# netx90_app register map
File version: 1.0
CPU: CM4 r0p1, little endian, MPU, FPU, 4 interrupt priority bits, 78 interrupts
Registers are 32-bit, read-write, reset 0x0 unless marked. A register's access mark holds for its fields unless they carry their own. Offsets are from the block's base; [hi:lo] are bit positions; {n}, {i} and the like mark numbered series; 'fields as' and 'values as' point back to an identical list; <NAME> marks a mode.

## mpwm_app
Base 0xFF802400
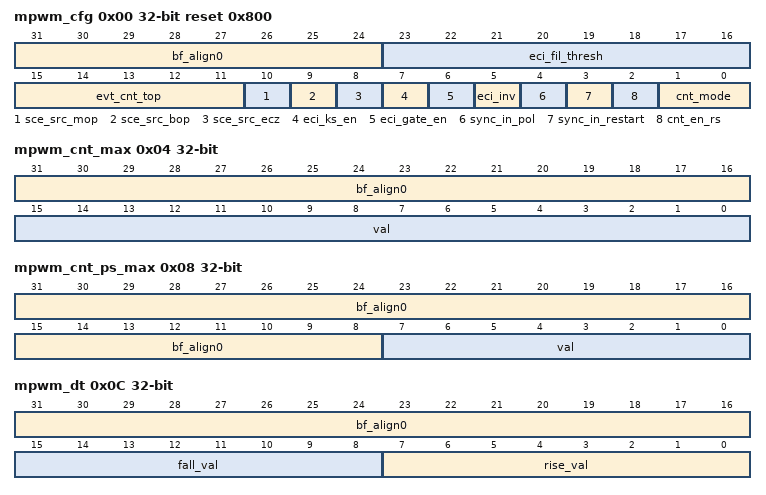
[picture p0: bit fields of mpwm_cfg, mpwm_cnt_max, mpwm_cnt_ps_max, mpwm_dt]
0x00 mpwm_cfg reset 0x800 (reset mask 0xFFFFFF) — Config register: General config bits for the MPWM module.
  [31:24] bf_align0 — bitField alignment value for aeabi compatibility
  [23:16] eci_fil_thresh — ECI filter threshold: Threshold value for the error condition input integral filter.
  [15:11] evt_cnt_top — evt_cnt_top Used to specify the maximum value of EVT_CNT. When EVT_CNT is zero and a begin of period )BOP) event occurs, an event counter zero (ECZ) event is emitted and EVT_CNT is reset to evt_cnt_top. If an begin of period event occurs and EVT_CNT is not zero, EVT_CNT is decremented. This mechanism can be used as an event prescaler to reduce the number of period interrupts from the MPWM module. Examples: If evt_cnt_top is zero, ECZ events and BOP events will coincide. If evt_cnt_top is one, ECZ events will appear every other period (half the frequency of BOP events). If evt_cnt_top is two, ECZ events will appear every third period (one third the frequency of BOP events).
  [10] sce_src_mop — sce_src_mop 1=emit shadow copy event on middle of PWM period bit
  [9] sce_src_bop — sce_src_bop 1=emit shadow copy event on beginning of PWM period
  [8] sce_src_ecz — sce_src_ecz 1=emit shadow copy event when event counter reaches zero
  [7] eci_ks_en — eci_ks_en Set 1 to enable synchronous error condition input (eci) kill switch. The synchronous eci kill switch is a flip flop that is set once eci is active. The eci kill switch can only be reset through MPWM_ECI_CMD. When the eci kill switch is set, all PWM module outputs are disabled.
  [6] eci_gate_en — eci_gate_en Set 1 to gate all pwm outputs with the integral filtered error control input. This means that the outputs will be disabled asynchronously whenever eci is active.
  [5] eci_inv — eci_inv This bit controls the polarity of the error condition input (eci). Set 0 for active high eci, 1 for active low eci.
  [4] sync_in_pol — Polarity of sync signal from trigger_latch unit 0: Sync on rising edge 1: Sync on falling edge
  [3] sync_in_restart — Restart at sync signal from trigger_latch unit 0: Restart counter only by restart command. 1: Restart counter at sync signal or by restart command.
  [2] cnt_en_rs — cnt_en_rs When this bit is one and sync_in is active, save the value of MPWM_CNT to the MPWM_CNT_RS (rs = read sync) register.
  [1:0] cnt_mode — Counter mode: 00: sawtooth 01: triangle 10: inv sawtooth 11: inv triangle
0x04 mpwm_cnt_max (reset mask 0xFFFF) — Counter top register: This is the maximum / top value for the PWM counter. In inverse sawtooth mode, MPWM_CNT will be loaded with MPWM_CNT_MAX after reaching zero or when restarting the counter. In sawtooth mode, MPWM_CNT will be reset to zero after reaching MPWM_CNT_MAX. In inverse sawtooth mode, MPWM_CNT will be set to MPWM_CNT_MAX when restarting the counter, and when it reaches MPWM_CNT_MAX while counting up, it will change to counting down. In inverse sawtooth mode, when MPWM_CNT reaches MPWM_CNT_MAX while counting up, it will change to counting down. In either sawtooth mode, the most significant bit must be zero. This is necessary to ensure a valid MPWM_ECNT. The CNT_MAX register must be at least 1 for correct operation of the counter.
  [31:16] bf_align0 — bitField alignment value for aeabi compatibility
  [15:0] val — Counter top value
0x08 mpwm_cnt_ps_max (reset mask 0xFF) — Counter prescaler max value register: The values of this register determines how often MPWM_CNT and the counters in the dead time generators will be updated. When setting MPWM_CNT_PS_MAX to n, MPWM_CNT will be updated every n + 1 system clock cycles. This register can be used to slow down operation of the counter.
  [31:8] bf_align0 — bitField alignment value for aeabi compatibility
  [7:0] val — Counter prescaler max value
0x0C mpwm_dt (reset mask 0xFFFF) — Dead time register: This is the number of dead (LS and HS off) cycles (prescaled by MPWM_CNT_PS) that the dead time generator inserts when the direct PWM signal changes from zero to one (rise_val) and from one to zero (fall_val). Set to zero for no dead cycles.
  [31:16] bf_align0 — bitField alignment value for aeabi compatibility
  [15:8] fall_val — Dead time cycles at falling edge of PWM signal
  [7:0] rise_val — Dead time cycles at rising edge of PWM signal
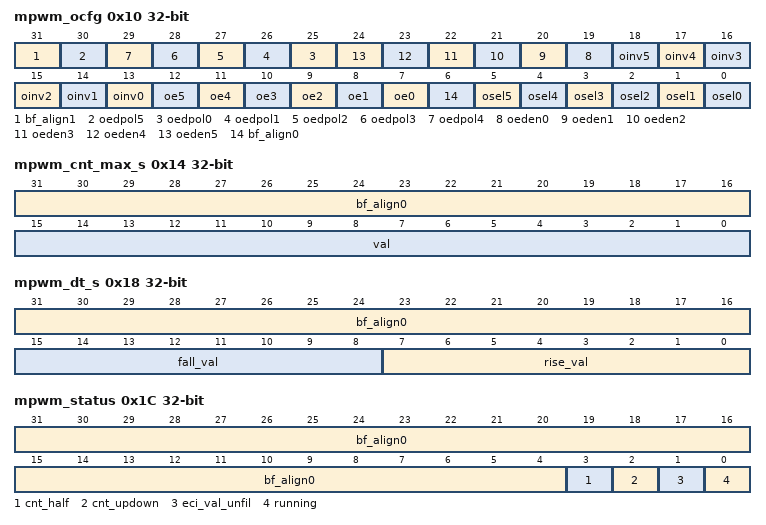
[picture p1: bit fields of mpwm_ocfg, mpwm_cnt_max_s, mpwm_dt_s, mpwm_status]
0x10 mpwm_ocfg (reset mask 0x7FFFFFBF) — Output section config register: Output select, enable, invert and edge detect values.
  [31] bf_align1 — bitField alignment value for aeabi compatibility
  [30] oedpol5 — Channel 5 edge detector polarity (0 = detect positive edge, 1 = detect negative edge)
  [n+25] oedpol{n} (n=0..4) — Channel {n} edge detector polarity
  [n+19] oeden{n} (n=0..5) — Channel {n} edge detector enable
  [n+13] oinv{n} (n=1..5) — Output {n} invert
  [13] oinv0 — Output 0 invert (see output section diagram)
  [n+7] oe{n} (n=1..5) — Output {n} enable
  [7] oe0 — Output 0 enable (see output section diagram)
  [6] bf_align0 — bitField alignment value for aeabi compatibility
  [5] osel5 — Output 5 selector: 0: compare channel 5 direct PWM output 1: dead time generator channel 2 LS
  [4] osel4 — Output 4 selector: 0: compare channel 4 direct PWM output 1: dead time generator channel 2 HS
  [3] osel3 — Output 3 selector: 0: compare channel 3 direct PWM output 1: dead time generator channel 1 LS
  [2] osel2 — Output 2 selector: 0: compare channel 2 direct PWM output 1: dead time generator channel 1 HS
  [1] osel1 — Output 1 selector: 0: compare channel 1 direct PWM output 1: dead time generator channel 0 LS
  [0] osel0 — Output 0 selector: 0: compare channel 0 direct PWM output 1: dead time generator channel 0 HS
0x14 mpwm_cnt_max_s (reset mask 0xFFFF) — Counter top shadow register: Shadow register for MPWM_CNT_TOP. After writing this register, an internal flag is set. If the internal flag is set, at the next occurence of a shadow copy event cnt_top will be overwritten by MPWM_CNT_MAX_S and the internal flag will be reset.
  [31:16] bf_align0 — bitField alignment value for aeabi compatibility
  [15:0] val — Counter top shadow value
0x18 mpwm_dt_s (reset mask 0xFFFF) — Dead time shadow register: Shadow register for MPWM_DT register.
  [31:16] bf_align0 — bitField alignment value for aeabi compatibility
  [15:8] fall_val — Dead time shadow value for falling edge of PWM signal
  [7:0] rise_val — Dead time shadow value for rising edge of PWM signal
0x1C mpwm_status ro (reset mask 0xF) — Status register: This register can be read to obtain information about the current status of the MPWM module.
  [31:4] bf_align0 — bitField alignment value for aeabi compatibility
  [3] cnt_half — count half: 0: counter is in first half period of triangle mode or inverted triangle mode or counter is in sawtooth or inverse sawtooth mode. 1: counter is in second half period of triangle mode or inverted triangle mode
  [2] cnt_updown — count updown 0: counter is counting down 1: counter is counting up
  [1] eci_val_unfil — Error Condition Input unfiltered: Read the current value of the error condition input before the digital integral filter. This bit is corrected for polarity, which means it reads zero for inactive, one for active.
  [0] running — MPWM is running
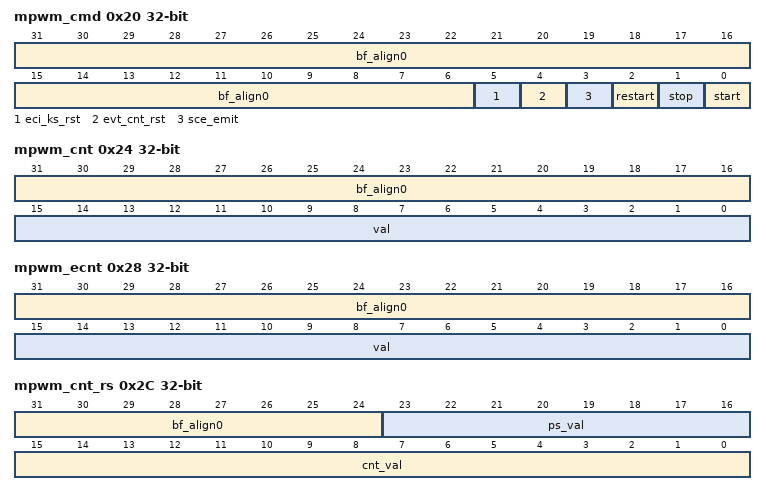
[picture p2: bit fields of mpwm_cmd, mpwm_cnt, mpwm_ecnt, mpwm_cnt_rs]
0x20 mpwm_cmd wo (reset mask 0x3F) — Command register:
  [31:6] bf_align0 — bitField alignment value for aeabi compatibility
  [5] eci_ks_rst — ECI kill switch reset: Command register to reset the eci kill switch.
  [4] evt_cnt_rst — Event Counter Reset
  [3] sce_emit — Copy shadow registers to corresponding registers
  [2] restart — Restart: Write 1 to this bit to reset MPWM_CNT and MPWM_CNT_PS and start counter operation. MPWM_CNT_PS is reset to MPWM_CNT_PS_MAX. In triangle and sawtooth mode, MPWM_CNT is reset to 0. In inverse triangle and inverse sawtooth mode, MPWM_CNT is reset to MPWM_CNT_MAX. If the restart and the stop bit are written as 1 in the same access, the MPWM_CNT and MPWM_CNT_PS registers will be reset but the counter will remain stopped.
  [1] stop — Stop: Write 1 to this bit to stop counter operation and prescaler operation.
  [0] start — Start: Write 1 to start counter operation and prescaler operation. This does not reset the counter state. If the counter operating before, it will resume operation from where it was stopped.
0x24 mpwm_cnt ro (reset mask 0xFFFF) — Counter: Global counter. Used for all the comparisons that then generate the PWM signals. See counter behaviour diagram.
  [31:16] bf_align0 — bitField alignment value for aeabi compatibility
  [15:0] val — value
0x28 mpwm_ecnt ro (reset mask 0xFFFF) — Extended counter: Counter extended by one bit to distinguish between counting up and down. See counter behaviour diagram. The content of this register is also exposed to the outside of this module to allow other system components to synchronize themselves to the MPWM counter.
  fields as mpwm_cnt
0x2C mpwm_cnt_rs ro (reset mask 0xFFFFFF) — Counter save register: When CFG.cnt_en_rs (rs = read sync) is set, this register is used to save the value of the MPWM_CNT and MPWM_CNT_PS register every time that sync_in becomes active.
  [31:24] bf_align0 — bitField alignment value for aeabi compatibility
  [23:16] ps_val — saved value of the MPWM_CNT_PS register
  [15:0] cnt_val — saved value of the MPWM_CNT register
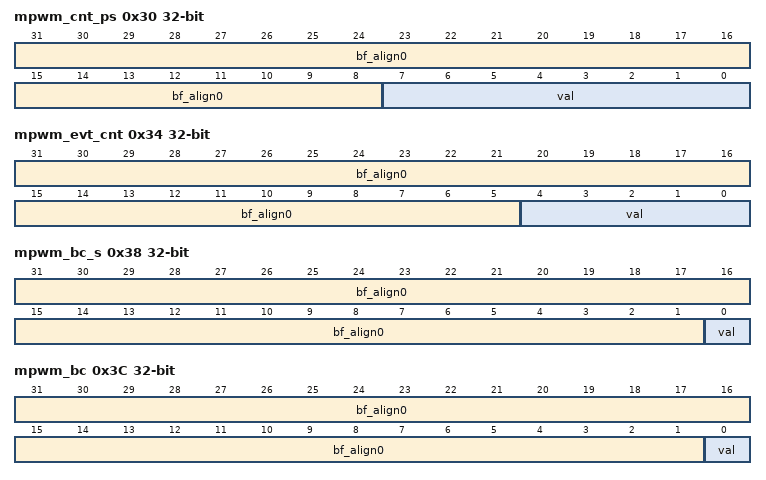
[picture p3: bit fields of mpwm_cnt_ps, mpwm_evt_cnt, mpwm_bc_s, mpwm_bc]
0x30 mpwm_cnt_ps ro (reset mask 0xFF) — Counter prescaler register: Internal counter that is responsible for determining, in which clock cycles cnt will be incremented / decremented. MPWM_CNT_PS is reloaded with MPWM_CNT_PS_MAX when it reaches zero. In every clock cycle, in which MPWM_CNT_PS is zero, cnt will be incremented / decremented.
  [31:8] bf_align0 — bitField alignment value for aeabi compatibility
  [7:0] val — value
0x34 mpwm_evt_cnt ro (reset mask 0x1F) — Event counter register: This counter counts down whenever a full PWM period is finished. When MPWM_EVT_CNT reaches zero, a event counter zero event is emitted and MPWM_EVT_CNT is reset to MPWM_EVT_CNT_TOP.
  [31:5] bf_align0 — bitField alignment value for aeabi compatibility
  [4:0] val — Current counter value
0x38 mpwm_bc_s (reset mask 0x1) — Brake chopper shadow register: Shadow register for the brake chopper output
  [31:1] bf_align0 — bitField alignment value for aeabi compatibility
  [0] val — value
0x3C mpwm_bc (reset mask 0x1) — Brake chopper register: The brake chopper output signal is determined by the value of this register.
  fields as mpwm_bc_s
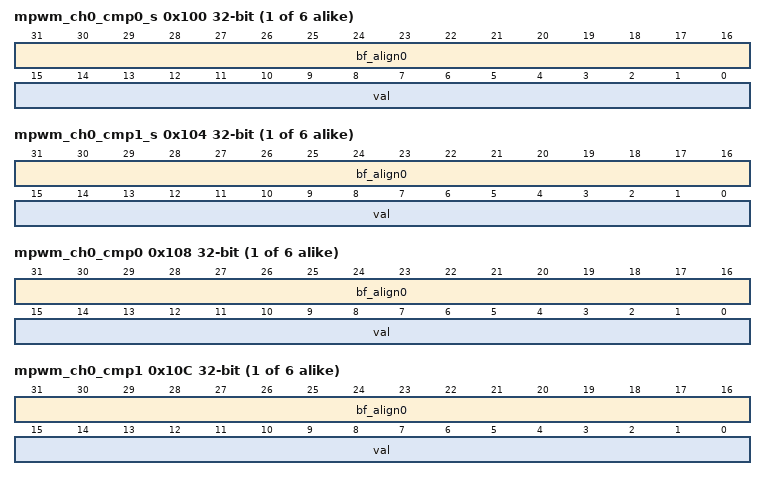
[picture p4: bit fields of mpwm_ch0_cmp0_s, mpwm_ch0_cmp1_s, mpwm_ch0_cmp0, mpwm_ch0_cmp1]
{0x100+0x20*i} mpwm_ch{i}_cmp0_s (reset mask 0xFFFF) (i=0..5) — Channel {i} compare value 0 shadow register: Compare value 0 shadow register for channel {i}.
  fields as mpwm_cnt
{0x104+0x20*i} mpwm_ch{i}_cmp1_s (reset mask 0xFFFF) (i=0..5) — Channel {i} compare value 1 shadow register: Compare value 1 shadow register for channel {i}.
  fields as mpwm_cnt
{0x108+0x20*i} mpwm_ch{i}_cmp0 (reset mask 0xFFFF) (i=0..5) — Channel {i} compare value 0 register: Compare value 0 for channel {i}.
  fields as mpwm_cnt
{0x10C+0x20*i} mpwm_ch{i}_cmp1 (reset mask 0xFFFF) (i=0..5) — Channel {i} compare value 1 register: Compare value 1 for channel {i}.
  fields as mpwm_cnt
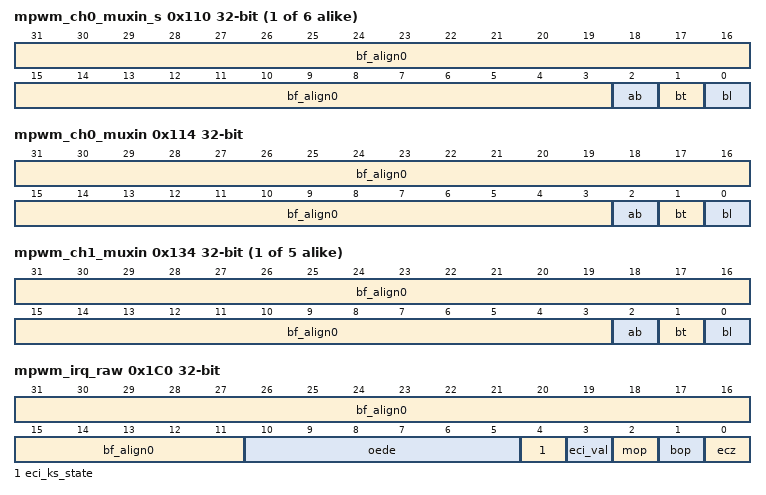
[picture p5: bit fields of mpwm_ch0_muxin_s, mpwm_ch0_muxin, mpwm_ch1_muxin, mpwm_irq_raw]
{0x110+0x20*i} mpwm_ch{i}_muxin_s (reset mask 0x7) (i=0..5) — Channel {i} multiplexer input shadow register: Shadow register for channel {i} multiplexer input register.
  [31:3] bf_align0 — bitField alignment value for aeabi compatibility
  [2] ab — above
  [1] bt — between
  [0] bl — below
0x114 mpwm_ch0_muxin (reset mask 0x7) — Channel 0 multiplexer input register: This register is central in determining the direct PWM output value of channel 0. When (CNT < CHX_CMP0) and (CNT < CHX_CMP1), then the direct PWM output signal is equal to CHX_MUXIN.bl (counter value is BeLow both compare values). When (CNT >= CHX_CMP0) and (CNT >= CHX_CMP1), then the direct PWM output signal is equal to CHX_MUXIN.ab (counter value is ABove both compare values). If neither is the case, CNT is BeTween CHX_CMP0 and CHX_CMP1 and the direct PWM output signal is equal to CHX_MUXIN.bt.
  fields as mpwm_ch0_muxin_s
{0x114+0x20*i} mpwm_ch{i}_muxin (reset mask 0x7) (i=1..5) — Channel {i} multiplexer input register: This register is central in determining the direct PWM output value of channel {i}. When (CHX_CMP0 $>=$ CNT) and (CHX_CMP1 $>=$ CNT), the direct PWM output signal is equal to CHX_MUXIN.bl (counter value is below both compare values). When (CHX_CMP0 $>=$ CNT) xor (CHX_CMP1 $>=$ CNT) is true, then the direct PWM output signal is equal to CHX_MUXIN.bt (counter value is between both compare values). When not (CHX_CMP0 $>=$ CNT) and not (CHX_CMP1 $>=$ CNT), then the direct PWM output signal is equal to CHX_MUXIN.ab (counter value is above both compare values).
  fields as mpwm_ch0_muxin_s
0x1C0 mpwm_irq_raw (reset mask 0x7FF) — Raw IRQ: Read access shows status of unmasked IRQs. IRQs are set automatically and reset by writing to this register: Write access with '1' resets the appropriate IRQ (if event irq, reset status irqs at their source). Write access with '0' does not influence this bit.
  [31:11] bf_align0 — bitField alignment value for aeabi compatibility
  [10:5] oede — event: output section edge detector
  [4] eci_ks_state — status: error condition kill switch state bit
  [3] eci_val — status: eci_val error condition input value bit after filter
  [2] mop — event: middle of PWM period bit
  [1] bop — event: beginning of PWM period bit
  [0] ecz — event: evt_counter reached zero bit
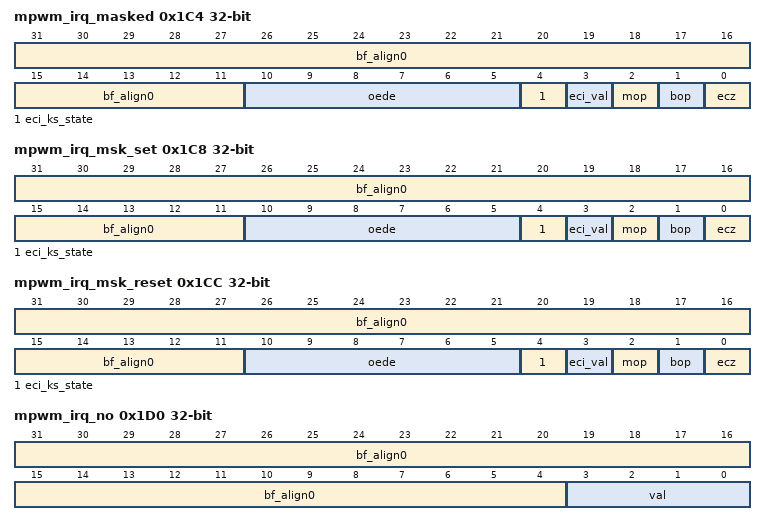
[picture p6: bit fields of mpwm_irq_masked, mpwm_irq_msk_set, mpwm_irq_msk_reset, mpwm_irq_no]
0x1C4 mpwm_irq_masked ro (reset mask 0x7FF) — Masked IRQ: Shows status of masked IRQs (as connected to ARM/xPIC).
  fields as mpwm_irq_raw
0x1C8 mpwm_irq_msk_set (reset mask 0x7FF) — IRQ enable mask: The IRQ mask enables interrupt requests for corresponding interrupt sources. As its bits might be changed by different software tasks, the IRQ mask register is not writable directly, but by set and reset masks: Write access with '1' sets interrupt mask bit. Write access with '0' does not influence this bit. Read access shows actual interrupt mask. Attention: Before activating interrupt mask, delete old pending interrupts by writing the same value to adr_mpwm_irq_raw.
  fields as mpwm_irq_raw
0x1CC mpwm_irq_msk_reset (reset mask 0x7FF) — IRQ disable mask: This is the corresponding reset mask to disable interrupt requests for corresponding interrupt sources: Write access with '1' resets interrupt mask bit. Write access with '0' does not influence this bit. Read access is undefined
  fields as mpwm_irq_raw
0x1D0 mpwm_irq_no ro (reset mask 0xF) — IRQ number: This shows the bit number of the lowest active bit in IRQ_MASKED or MAX+1 when no bit is set.
  [31:4] bf_align0 — bitField alignment value for aeabi compatibility
  [3:0] val — lowest active IRQ number
